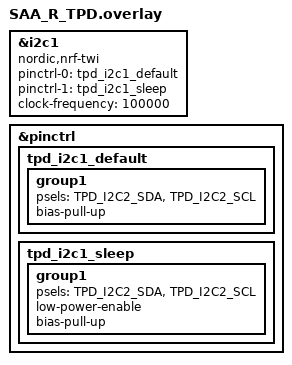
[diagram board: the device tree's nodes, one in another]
#include "SAA_pins.dtsi"

&i2c1 {
    status = "okay";
    compatible = "nordic,nrf-twi";
    pinctrl-0 = <&tpd_i2c1_default>;
    pinctrl-1 = <&tpd_i2c1_sleep>;
    pinctrl-names = "default", "sleep";
    clock-frequency = <100000>;
};

&pinctrl {
    tpd_i2c1_default: tpd_i2c1_default {
        group1 {
            psels = <TPD_I2C2_SDA>,
                    <TPD_I2C2_SCL>;
            bias-pull-up;
        };
    };

    tpd_i2c1_sleep: tpd_i2c1_sleep {
        group1 {
            psels = <TPD_I2C2_SDA>,
                    <TPD_I2C2_SCL>;
            low-power-enable;
            bias-pull-up;
        };
    };
};

#define TPD_BUS i2c1
#include "SAA_R_tpd_device.dtsi"
#undef TPD_BUS
